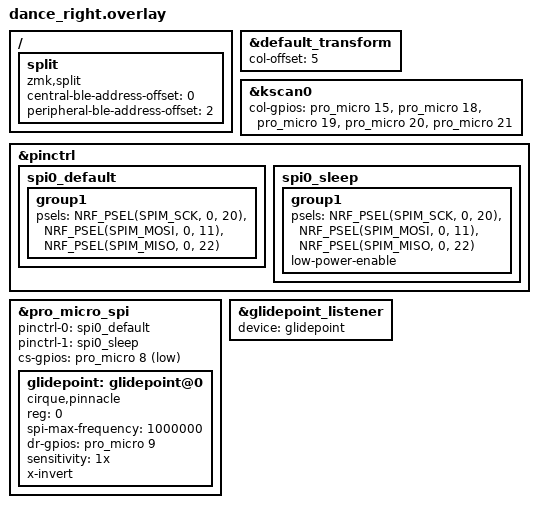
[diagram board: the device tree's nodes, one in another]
/*
 * Copyright (c) 2020 Pete Johanson
 *
 * SPDX-License-Identifier: MIT
 */
#include "dance.dtsi"

/ {
    // Split configuration for right peripheral
    split: split {
        compatible = "zmk,split";
        central-ble-address-offset = <0>;      // Central (dongle) = address 0
        peripheral-ble-address-offset = <2>;   // Right = address 2
    };
};

&default_transform {
    col-offset = <5>;
};

&kscan0 {
    col-gpios
        = <&pro_micro 15 GPIO_ACTIVE_HIGH>
        , <&pro_micro 18 GPIO_ACTIVE_HIGH>
        , <&pro_micro 19 GPIO_ACTIVE_HIGH>
        , <&pro_micro 20 GPIO_ACTIVE_HIGH>
        , <&pro_micro 21 GPIO_ACTIVE_HIGH>
        ;
};

//added for trackpad 8/18
&pinctrl {
    /* configuration for spi0 device, default state */
    spi0_default: spi0_default {
        /* node name is arbitrary */
        group1 {
            /* main role: configure P0.20 (D3) as SPI clock, P0.11 (D7) as SPI MOSI, P0.22 (D4) as SPI MISO */
            psels = <NRF_PSEL(SPIM_SCK, 0, 20)>,
                    <NRF_PSEL(SPIM_MOSI, 0, 11)>,
                    <NRF_PSEL(SPIM_MISO, 0, 22)>;
        };
    };
    /* configuration for spi0 device, sleep state */
    spi0_sleep: spi0_sleep {
        group1 {
            /* main role: configure P0.20 (D3) as SPI clock, P0.11 (D7) as SPI MOSI, P0.22 (D4) as SPI MISO */
            psels = <NRF_PSEL(SPIM_SCK, 0, 20)>,
                    <NRF_PSEL(SPIM_MOSI, 0, 11)>,
                    <NRF_PSEL(SPIM_MISO, 0, 22)>;
            low-power-enable;
        };
    };
};

&pro_micro_spi {
    status = "okay";
    pinctrl-0 = <&spi0_default>;
    pinctrl-1 = <&spi0_sleep>;
    pinctrl-names = "default", "sleep";

    cs-gpios = <&pro_micro 8 GPIO_ACTIVE_LOW>;

    glidepoint: glidepoint@0 {
        compatible = "cirque,pinnacle";
        reg = <0>;
        spi-max-frequency = <1000000>;
        status = "okay";
        dr-gpios = <&pro_micro 9 (GPIO_ACTIVE_HIGH)>;

        sensitivity = "1x";
        x-invert;
    };
};

&glidepoint_listener {
    status = "okay";
    device = <&glidepoint>;
};

// end of addition for trackpad

